# TLSR826X register map
File version: 0.1
Registers are 8-bit, access not given, no defined reset value unless marked. A register's access mark holds for its fields unless they carry their own. Offsets are from the block's base; [hi:lo] are bit positions; {n}, {i} and the like mark numbered series.

## DFIFO — Auto-generated from section 'dfifo'
Base 0x00800B00
0x00 DFIFO0_BUF 32-bit — Auto-generated from dfifo0_buf; aliases: DFIFO0_ADDR
0x02 DFIFO0_SIZE — Auto-generated from dfifo0_size
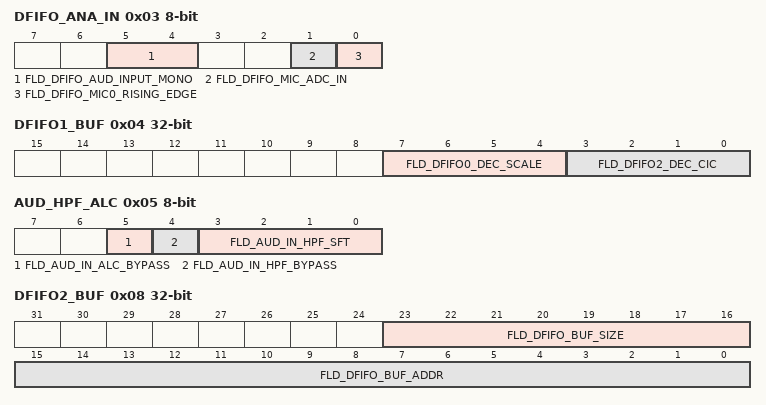
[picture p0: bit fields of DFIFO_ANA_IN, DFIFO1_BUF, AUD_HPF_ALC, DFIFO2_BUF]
0x03 DFIFO_ANA_IN — Auto-generated from dfifo_ana_in
  [5:4] FLD_DFIFO_AUD_INPUT_MONO, [1] FLD_DFIFO_MIC_ADC_IN, [0] FLD_DFIFO_MIC0_RISING_EDGE
0x04 DFIFO1_BUF 32-bit — Auto-generated from dfifo1_buf; aliases: DFIFO_SCALE
  [7:4] FLD_DFIFO0_DEC_SCALE, [3:0] FLD_DFIFO2_DEC_CIC
0x05 AUD_HPF_ALC — Auto-generated from aud_hpf_alc
  [5] FLD_AUD_IN_ALC_BYPASS, [4] FLD_AUD_IN_HPF_BYPASS, [3:0] FLD_AUD_IN_HPF_SFT
0x06 AUD_ALC_VOL — Auto-generated from aud_alc_vol
0x08 DFIFO2_BUF 32-bit — Auto-generated from dfifo2_buf
  [23:16] FLD_DFIFO_BUF_SIZE, [15:0] FLD_DFIFO_BUF_ADDR
0x10 AUDIO_WR_PTR 16-bit — Auto-generated from audio_wr_ptr
  [7] FLDA_32K_TRIGGER_TIMER, [7] FLDA_DCDC_2P8_PWDN, [7] FLDA_LPF_PWDN, [7] FLDA_NDIV_EN, [7] FLDA_PA_TX_EXT_C1_EN, [7] FLDA_PLL_LDO2_PWDN, [7] FLDA_PM_PWDN_EN, [7] FLDA_PWDN_ISO_EN, [7] FLDA_REG_DC_MOD0, [7] FLDA_RF_PEAK_DET2_EN, [7] FLDA_RX_ADC_PWDN, [7] FLDA_RX_PGA_PWDN, [7] FLDA_TEMPSEN_PWDN, [7] FLDA_TXCALDIV2BUF_PWDN, [7] FLDA_TX_MAN_EN, [7] FLDA_XTAL_COM_REF, [7:6] FLDA_AUD_PRE_GAIN_LEFT, [7:6] FLDA_BP_PLL_R_DIV, [6] FLDA_COMP_PWDN, [6] FLDA_DCDC_OUT_6P6_SEL, [7:6] FLDA_LDO_SETTING2_RSV, [6] FLDA_MASH2_EN, [7:6] FLDA_PLL_LDO_DS, [6] FLDA_PLL_LDO_PWDN, [6] FLDA_PM_PWDN_LDO, [6] FLDA_PWDN_BUF_DIG, [6] FLDA_PWDN_REG456_EN, [6] FLDA_REFBUF_PWDN, [6] FLDA_RF_PEAK_DET1_EN, [6] FLDA_RX_LNA_ON, [6] FLDA_RX_MAN_EN, [6] FLDA_RX_PGA_COMP_EN, [7:6] FLDA_XTAL_VOLT, [5] FLDA_BGIREF_3V_PWDN, [5] FLDA_DCDC_OUT_2P8_SEL, [5] FLDA_INTG_PFD_S1, [6:5] FLDA_LDO_TRIM_3V, [6:5] FLDA_PLL_DPLL_REF, [5] FLDA_PLL_DS_LDO_PWDN, [5] FLDA_PM_RESV1, [5] FLDA_PULLDN_DIGLDO, [5] FLDA_PWDN_BUF_RCCAL, [5] FLDA_PWDN_LOW_LEAK_LDO, [6:5] FLDA_RX_ADC_DLY_CTRL, [6:5] FLDA_RX_IB1, [5] FLDA_TEST_IQ_MIXER_EN, [7:5] FLDA_VCO_TXI, [7:5] FLDA_VOL_BAND_GAP, [n] FLDA_WKUP_POL_PAD{n} (n=0..5), [5] FLDA_XTAL_PWDN, [4] FLDA_32K_RST_TIMER, [5:4] FLDA_AUD_PRE_GAIN_RIGHT, [7:4] FLDA_AUD_PST_GAIN_LEFT, [4] FLDA_DCDC_IN_2P8_PS, [7:4] FLDA_DELAY_AFTER_WAKEUP, [4] FLDA_INTG_PFD_S0, [4] FLDA_LDO_PWDN, [4] FLDA_PLL_BG_PWDN, [5:4] FLDA_PLL_LDO_B2, [4] FLDA_PM_WAKEUP_POL, [4] FLDA_PULLDN_LOLDO, [4] FLDA_PWDN_CLK_RF, [4] FLDA_PWDN_SAR_ADC, [4] FLDA_TEST_PGA_IN_EN, [3] FLDA_32K_CNT_CONTINUOUS, [3] FLDA_32K_TIMER_EN, [3] FLDA_32M_XTAL_PWDN, [3] FLDA_AUD_MUTE_LEFT, [3] FLDA_BP_PLL_VCO_SEL, [3] FLDA_DCDC_6P75_PWDN, [5:3] FLDA_PA_TX_UNIT, [3] FLDA_PFD_NP_INTG, [3] FLDA_PWDN_CLK_BB, [3] FLDA_PWDN_RX, [7:3] FLDA_RX_INTG_N0, [5:3] FLDA_RX_LNA_BIAS, [3] FLDA_RX_RF_LDO_PWDN, [3] FLDA_TEST_PGA_OUT_EN, [7:3] FLDA_VCO_CAL_COMP, [4:3] FLDA_VOL_LDO_OUTPUT, [3] FLDA_XTAL_LDO_TRIM, [2] ENDIF_FLDA_PWDN_TX, [2] FLDA_32K_CONTINUE_MODE, [2] FLDA_32M_RC_PWDN, [2] FLDA_AUD_MUTE_RIGHT, [2] FLDA_BP_PLL_4ST_VCO_PWDN, [2] FLDA_DCDC_RESETB, [2] FLDA_IDIV2_UP_TX, [2] FLDA_LDO_ANA_LDOTRIM, [4:2] FLDA_PLL_DPLL_ADJ, [3:2] FLDA_PM_RESV0, [2] FLDA_RF_PEAK_DET_DLY3_EN, [2] FLDA_RX_ANA_LDO_PWDN, [5:2] FLDA_RX_PGA_CAP_CTRL, [3:2] FLDA_RX_RF_LDO_O_CTRL, [4:2] FLDA_VCO_RXI, [1] ELSE_FLDA_RESET_32K_TIMER, [1] FLDA_32K_XTAL_PWDN, [1] FLDA_AUD_PWDN_RIGHT, [1] FLDA_BG_I_EXT_PWDN, [1] FLDA_BP_PLL_3ST_VCO_PWDN, [1] FLDA_IDIV2_UP_RX, [7:1] FLDA_INTG_RXCAP, [1] FLDA_PM_WAKEUP_32K_SEL, [1] FLDA_RF_PEAK_DET_DLY2_EN, [1] FLDA_RNS_PWDN, [4:1] FLDA_RX_ADC_CTUNE, [2:1] FLDA_RX_IB, [1] FLDA_RX_PGA_BW_TUNE, [0] FLDA_32K_RC_PWDN, [1:0] FLDA_32K_THR3_H, [3:0] FLDA_AUD_PST_GAIN_RIGHT, [0] FLDA_AUD_PWDN_LEFT, [0] FLDA_BP_PLL_CP_PWDN, [0] FLDA_DCDC_RESV, [0] FLDA_DPLL_EN, [5:0] FLDA_INTG_RDIV, [2:0] FLDA_LDO_SEL_ATB, [4:0] FLDA_PA_TX_BIAS, [2:0] FLDA_PFD_MUX_L, [1:0] FLDA_PLL_DPLL, [5:0] FLDA_PLL_DPLL_WAIT, [0] FLDA_PM_WAKEUP_FROM_DIG, [0] FLDA_PWDN_INTG_PLL, [0] FLDA_PWDN_OSC_32K_EN, [0] FLDA_RF_PEAK_DET_DLY1_EN, [0] FLDA_RF_TEST_PWDN, [0] FLDA_RX_ADC_COMPLEX_EN, [1:0] FLDA_RX_ANA_LDO_O_CTRL, [4:0] FLDA_RX_INTG_N1, [2:0] FLDA_RX_LNA_OUT_TUNE, [1:0] FLDA_RX_LOLDO_OUTCTRL, [0] FLDA_RX_LO_LDO_PWDN, [0] FLDA_RX_PGA_IQ_SWAP_EN, [1:0] FLDA_TX_IB, [2:0] FLDA_VOL_LDO_RESV, [4:0] FLDA_XTAL_CS, [4:0] FLDA_XTAL_FREQ_OFF
